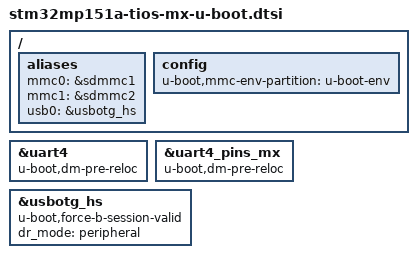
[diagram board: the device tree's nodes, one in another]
// SPDX-License-Identifier: (GPL-2.0-or-later OR BSD-3-Clause)
/*
 * Copyright (C) 2023, STMicroelectronics - All Rights Reserved
 * Author: STM32CubeMX code generation for STMicroelectronics.
 */

/* For more information on Device Tree configuration, please refer to
 * https://wiki.st.com/stm32mpu/wiki/Category:Device_tree_configuration
 */

/* USER CODE BEGIN includes */
#include "stm32mp15-scmi-u-boot.dtsi"
/* USER CODE END includes */

/ {

	/* USER CODE BEGIN root */
	aliases{
		mmc0 = &sdmmc1;
		mmc1 = &sdmmc2;
		usb0 = &usbotg_hs;
	};
	config{
		u-boot,mmc-env-partition = "u-boot-env";
	};
	/* USER CODE END root */

}; /*root*/

/* USER CODE BEGIN addons */
&uart4{
	u-boot,dm-pre-reloc;
};
&uart4_pins_mx {
	u-boot,dm-pre-reloc;
};
&usbotg_hs {
	u-boot,force-b-session-valid;
	dr_mode = "peripheral";
};
/* USER CODE END addons */

